# MB9AF42xK register map
File version: 1.0
CPU: 
Registers are 8-bit, read-write, reset 0x0 unless marked. A register's access mark holds for its fields unless they carry their own. Offsets are from the block's base; [hi:lo] are bit positions; {n}, {i} and the like mark numbered series.

## DAC — peripheral DAC
Base 0x40028000
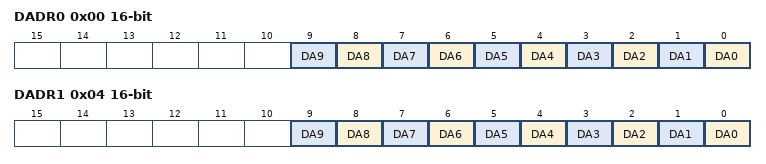
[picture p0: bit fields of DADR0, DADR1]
0x00 DADR0 16-bit reset not defined
  [n] DA{n} (n=0..9)
0x02 DACR0 reset not defined
  [0] DAE
0x04 DADR1 16-bit reset not defined
  [n] DA{n} (n=0..9)
0x06 DACR1 reset not defined
  [0] DAE

## EXTI — peripheral EXTI
Base 0x40030000
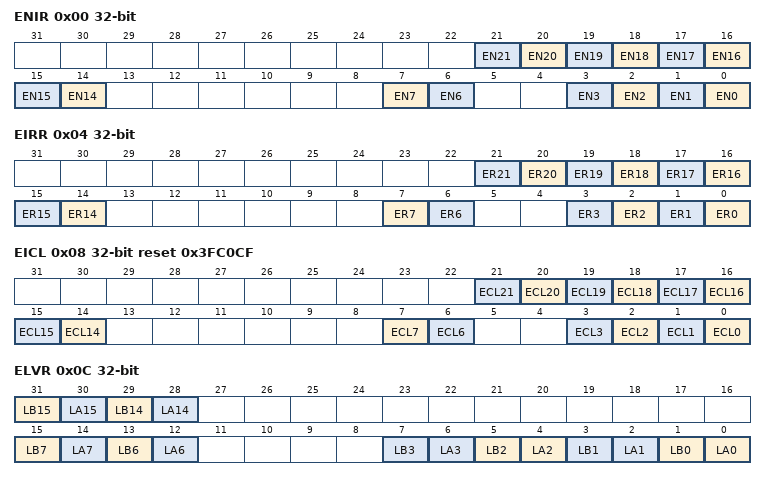
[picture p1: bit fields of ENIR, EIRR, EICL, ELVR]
0x00 ENIR 32-bit
  [n] EN{n} (n=14..21), [7] EN7, [6] EN6, [n] EN{n} (n=0..3)
0x04 EIRR 32-bit ro reset not defined
  [n] ER{n} rw (n=14..21), [7] ER7 rw, [6] ER6 rw, [n] ER{n} rw (n=0..3)
0x08 EICL 32-bit reset 0x3FC0CF
  [n] ECL{n} (n=14..21), [7] ECL7, [6] ECL6, [n] ECL{n} (n=0..3)
0x0C ELVR 32-bit
  [31] LB15, [30] LA15, [29] LB14, [28] LA14, [15] LB7, [14] LA7, [13] LB6, [12] LA6, [2n+1] LB{n} (n=0..3), [2n] LA{n} (n=0..3)
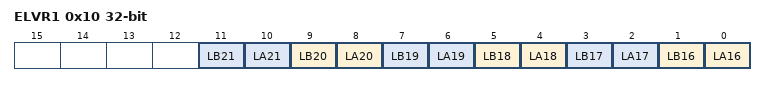
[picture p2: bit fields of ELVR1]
0x10 ELVR1 32-bit
  [2n-31] LB{n} (n=16..21), [2n-32] LA{n} (n=16..21)
0x14 NMIRR ro
  [0] NR
0x18 NMICL reset 0x1
  [0] NCL

## INTREQ — peripheral INTREQ
Base 0x40031000
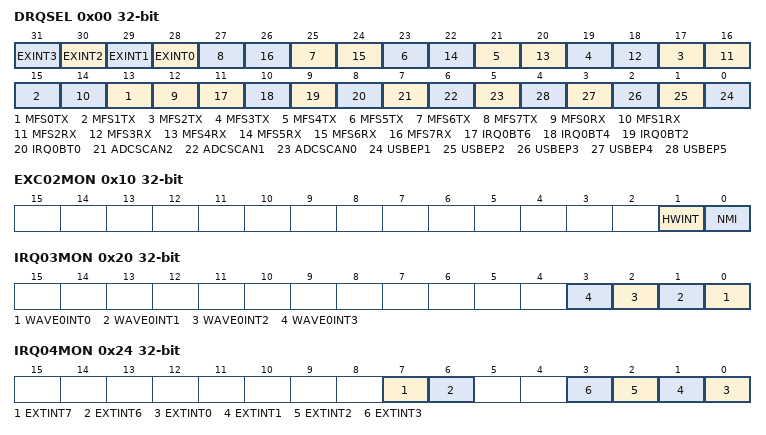
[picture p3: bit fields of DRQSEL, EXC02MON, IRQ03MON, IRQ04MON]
0x00 DRQSEL 32-bit
  [n+28] EXINT{n} (n=0..3), [2n+13] MFS{n}TX (n=0..7), [2n+12] MFS{n}RX (n=0..7), [11] IRQ0BT6, [10] IRQ0BT4, [9] IRQ0BT2, [8] IRQ0BT0, [7] ADCSCAN2, [6] ADCSCAN1, [5] ADCSCAN0, [n-1] USBEP{n} (n=1..5)
0x0B ODDPKS reset not defined
0x0C IRQCMODE 32-bit
  [0] IRQCMODE
0x10 EXC02MON 32-bit ro
  [1] HWINT, [0] NMI
0x14 IRQ00MON 32-bit ro
  [0] FCSINT
0x18 IRQ01MON 32-bit ro
  [0] SWWDTINT
0x1C IRQ02MON 32-bit ro
  [0] LVDINT
0x20 IRQ03MON 32-bit ro
  [n] WAVE0INT{n} (n=0..3)
0x24 IRQ04MON 32-bit ro
  [7] EXTINT7, [6] EXTINT6, [n] EXTINT{n} (n=0..3)
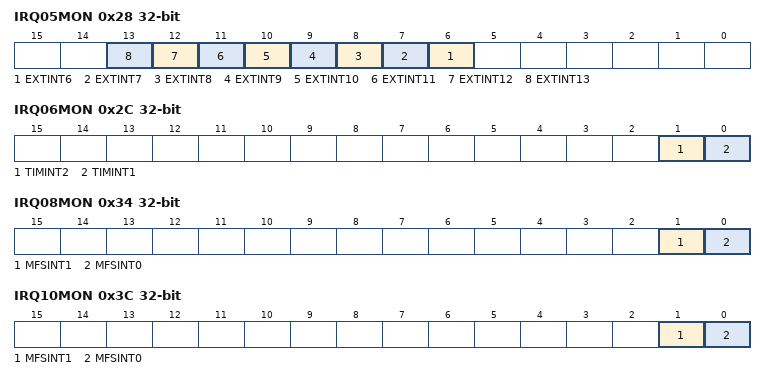
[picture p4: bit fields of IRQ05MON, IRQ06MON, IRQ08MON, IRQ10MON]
0x28 IRQ05MON 32-bit ro
  [n] EXTINT{n} (n=6..13)
0x2C IRQ06MON 32-bit ro
  [1] TIMINT2, [0] TIMINT1
0x30 IRQ07MON 32-bit ro
  [0] MFSINT0
0x34 IRQ08MON 32-bit ro
  [1] MFSINT1, [0] MFSINT0
0x38 IRQ09MON 32-bit ro
  [0] MFSINT0
0x3C IRQ10MON 32-bit ro
  [1] MFSINT1, [0] MFSINT0
0x40 IRQ11MON 32-bit ro (reset mask 0x1)
0x44 IRQ12MON 32-bit ro (reset mask 0x3)
0x48 IRQ13MON 32-bit ro
  [0] MFSINT0
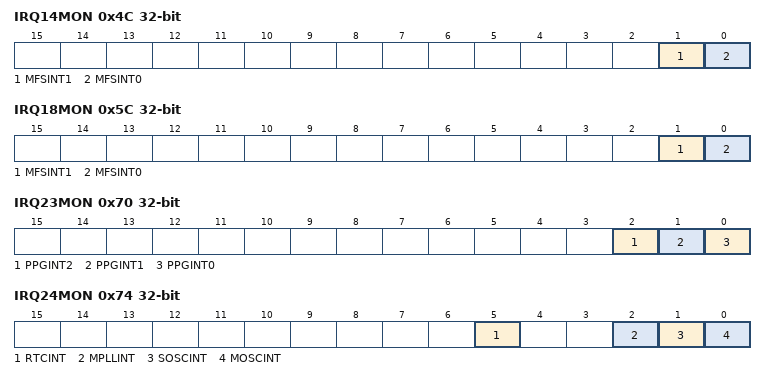
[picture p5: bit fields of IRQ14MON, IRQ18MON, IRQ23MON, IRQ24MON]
0x4C IRQ14MON 32-bit ro
  [1] MFSINT1, [0] MFSINT0
0x50 IRQ15MON 32-bit ro reset not defined
0x54 IRQ16MON 32-bit ro reset not defined
0x58 IRQ17MON 32-bit ro
  [0] MFSINT0
0x5C IRQ18MON 32-bit ro
  [1] MFSINT1, [0] MFSINT0
{0x14+4i} IRQ{i}MON 32-bit ro reset not defined (i=19..22)
0x70 IRQ23MON 32-bit ro
  [2] PPGINT2, [1] PPGINT1, [0] PPGINT0
0x74 IRQ24MON 32-bit ro
  [5] RTCINT, [2] MPLLINT, [1] SOSCINT, [0] MOSCINT
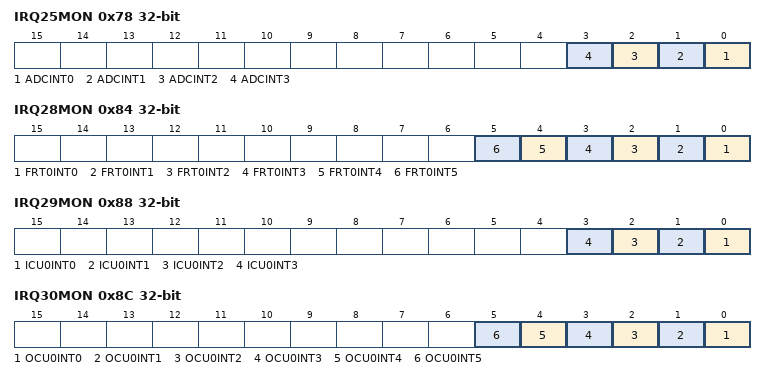
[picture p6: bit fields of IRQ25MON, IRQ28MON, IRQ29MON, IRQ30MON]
0x78 IRQ25MON 32-bit ro
  [n] ADCINT{n} (n=0..3)
0x7C IRQ26MON 32-bit ro reset not defined
0x80 IRQ27MON 32-bit ro reset not defined
0x84 IRQ28MON 32-bit ro
  [n] FRT0INT{n} (n=0..5)
0x88 IRQ29MON 32-bit ro
  [n] ICU0INT{n} (n=0..3)
0x8C IRQ30MON 32-bit ro reset not defined
  [n] OCU0INT{n} (n=0..5)
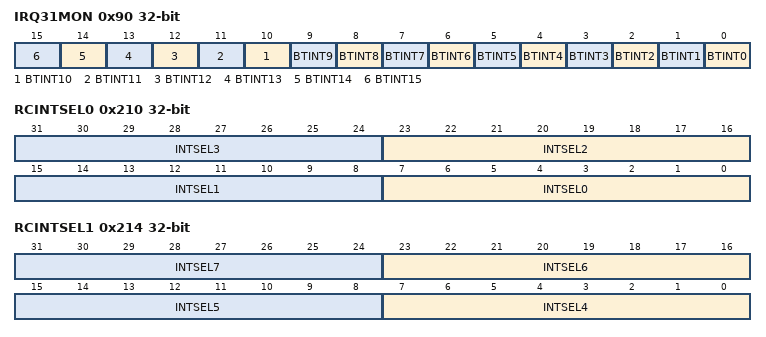
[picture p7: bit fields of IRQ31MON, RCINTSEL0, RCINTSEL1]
0x90 IRQ31MON 32-bit ro
  [n] BTINT{n} (n=0..15)
0x94 IRQ32MON 32-bit ro reset not defined
0x98 IRQ33MON 32-bit ro
  [0] CAN1NT
{0x14+4i} IRQ{i}MON 32-bit ro reset not defined (i=34..46)
0xD0 IRQ47MON 32-bit ro
  [11] FLASHINT
0x210 RCINTSEL0 32-bit
  [8n+7:8n] INTSEL{n} (n=0..3)
0x214 RCINTSEL1 32-bit
  [8n-25:8n-32] INTSEL{n} (n=4..7)

## GPIO — peripheral GPIO
Base 0x40033000
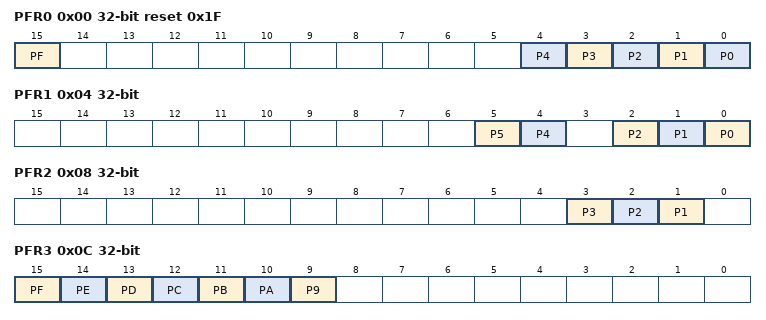
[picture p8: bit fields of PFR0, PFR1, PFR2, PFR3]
0x00 PFR0 32-bit reset 0x1F
  [15] PF, [n] P{n} (n=0..4)
0x04 PFR1 32-bit (reset mask 0x3E)
  [5] P5, [4] P4, [2] P2, [1] P1, [0] P0
0x08 PFR2 32-bit
  [3] P3, [2] P2, [1] P1
0x0C PFR3 32-bit
  [15] PF, [14] PE, [13] PD, [12] PC, [11] PB, [10] PA, [9] P9
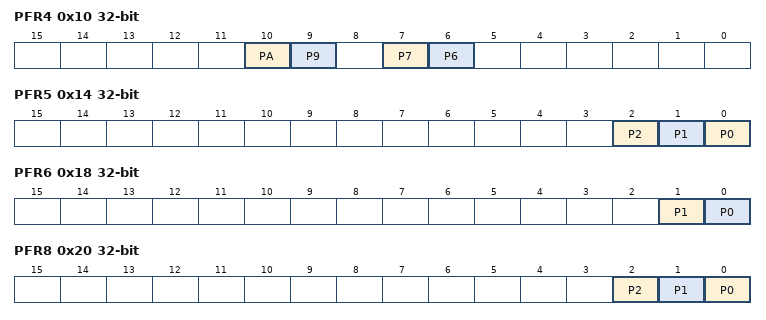
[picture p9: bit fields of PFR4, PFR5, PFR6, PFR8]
0x10 PFR4 32-bit
  [10] PA, [9] P9, [7] P7, [6] P6
0x14 PFR5 32-bit
  [2] P2, [1] P1, [0] P0
0x18 PFR6 32-bit
  [1] P1, [0] P0
0x20 PFR8 32-bit
  [2] P2, [1] P1, [0] P0
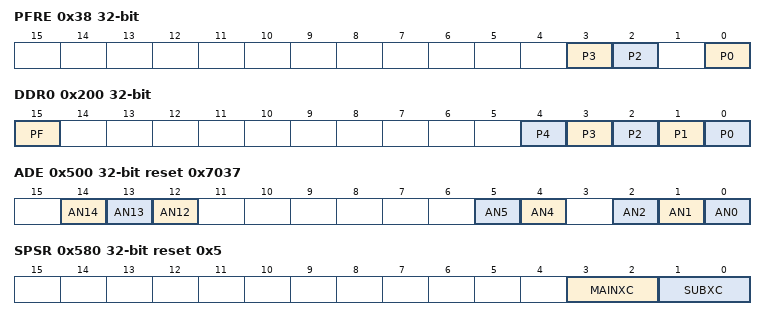
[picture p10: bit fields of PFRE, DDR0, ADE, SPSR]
0x38 PFRE 32-bit
  [3] P3, [2] P2, [0] P0
{0x100+4i} PCR{i} 32-bit reset not defined (i=0..6)
0x120 PCR8 32-bit reset not defined
0x138 PCRE 32-bit reset not defined
0x200 DDR0 32-bit
  [15] PF, [n] P{n} (n=0..4)
{0x200+4i} DDR{i} 32-bit reset not defined (i=1..6)
0x220 DDR8 32-bit reset not defined
0x238 DDRE 32-bit reset not defined
{0x300+4i} PDIR{i} 32-bit reset not defined (i=0..6)
0x320 PDIR8 32-bit reset not defined
0x338 PDIRE 32-bit reset not defined
{0x400+4i} PDOR{i} 32-bit reset not defined (i=0..6)
0x420 PDOR8 32-bit reset not defined
0x438 PDORE 32-bit reset not defined
0x500 ADE 32-bit reset 0x7037
  [14] AN14, [13] AN13, [12] AN12, [5] AN5, [4] AN4, [2] AN2, [1] AN1, [0] AN0
0x580 SPSR 32-bit reset 0x5
  [3:2] MAINXC, [1:0] SUBXC
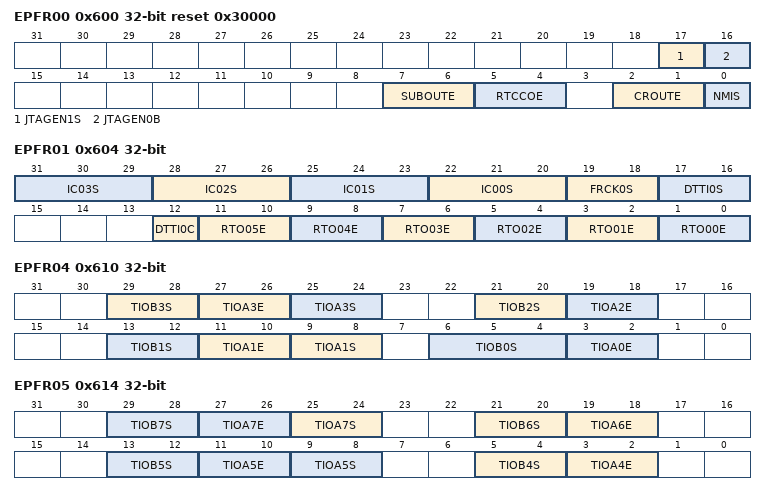
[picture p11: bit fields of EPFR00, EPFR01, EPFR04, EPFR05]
0x600 EPFR00 32-bit reset 0x30000
  [17] JTAGEN1S, [16] JTAGEN0B, [7:6] SUBOUTE, [5:4] RTCCOE, [2:1] CROUTE, [0] NMIS
0x604 EPFR01 32-bit
  [3n+22:3n+20] IC{n:02}S (n=0..3), [19:18] FRCK0S, [17:16] DTTI0S, [12] DTTI0C, [2n+1:2n] RTO{n:02}E (n=0..5)
0x608 EPFR02 32-bit reset not defined
0x60C EPFR03 32-bit reset not defined
0x610 EPFR04 32-bit
  [29:28] TIOB3S, [8n+3:8n+2] TIOA{n}E (n=0..3), [25:24] TIOA3S, [21:20] TIOB2S, [13:12] TIOB1S, [9:8] TIOA1S, [6:4] TIOB0S
0x614 EPFR05 32-bit
  [8n-27:8n-28] TIOB{n}S (n=4..7), [8n-29:8n-30] TIOA{n}E (n=4..7), [25:24] TIOA7S, [9:8] TIOA5S
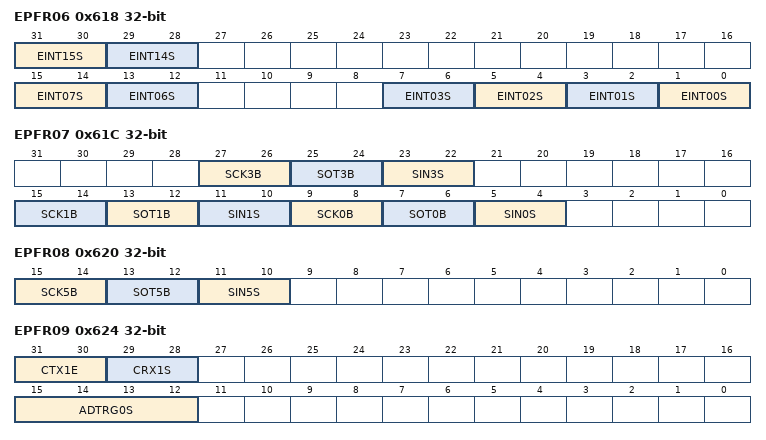
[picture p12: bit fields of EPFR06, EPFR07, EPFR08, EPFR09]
0x618 EPFR06 32-bit
  [31:30] EINT15S, [29:28] EINT14S, [15:14] EINT07S, [13:12] EINT06S, [2n+1:2n] EINT{n:02}S (n=0..3)
0x61C EPFR07 32-bit
  [27:26] SCK3B, [25:24] SOT3B, [23:22] SIN3S, [15:14] SCK1B, [13:12] SOT1B, [11:10] SIN1S, [9:8] SCK0B, [7:6] SOT0B, [5:4] SIN0S
0x620 EPFR08 32-bit
  [15:14] SCK5B, [13:12] SOT5B, [11:10] SIN5S
0x624 EPFR09 32-bit
  [31:30] CTX1E, [29:28] CRX1S, [15:12] ADTRG0S
{0x600+4i} EPFR{i} 32-bit reset not defined (i=10..14)
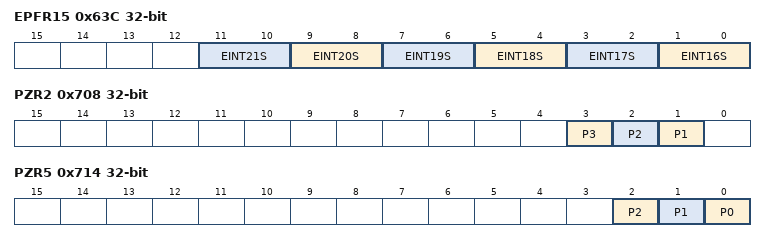
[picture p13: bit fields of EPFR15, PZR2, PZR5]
0x63C EPFR15 32-bit
  [2n-31:2n-32] EINT{n}S (n=16..21)
{0x600+4i} EPFR{i} 32-bit reset not defined (i=16..18)
0x708 PZR2 32-bit
  [3] P3, [2] P2, [1] P1
0x714 PZR5 32-bit
  [2] P2, [1] P1, [0] P0
0x718 PZR6 32-bit
  [0] P0
